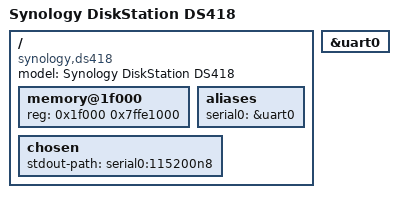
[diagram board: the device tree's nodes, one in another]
/dts-v1/;
#include "rtd1296.dtsi"
/ {
	compatible = "synology,ds418", "realtek,rtd1296";
	model = "Synology DiskStation DS418";
	memory@1f000 {
		device_type = "memory";
		reg = <0x1f000 0x7ffe1000>;  
	};
	aliases {
		serial0 = &uart0;
	};
	chosen {
		stdout-path = "serial0:115200n8";
	};
};
&uart0 {
	status = "okay";
};
